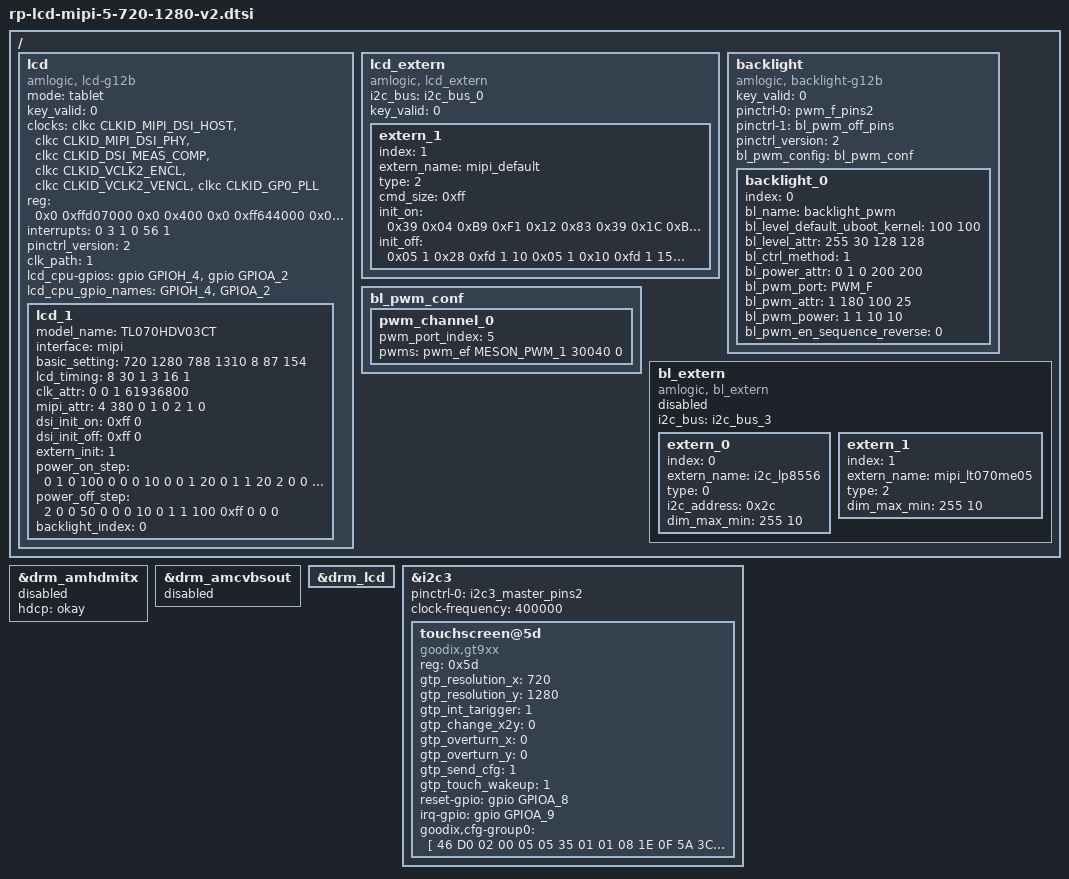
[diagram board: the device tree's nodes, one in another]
/*
 * arch/arm/boot/dts/amlogic/mesong12b_skt-panel.dtsi
 *
 * Copyright (C) 2016 Amlogic, Inc. All rights reserved.
 *
 * This program is free software; you can redistribute it and/or modify
 * it under the terms of the GNU General Public License as published by
 * the Free Software Foundation; either version 2 of the License, or
 * (at your option) any later version.
 *
 * This program is distributed in the hope that it will be useful, but WITHOUT
 * ANY WARRANTY; without even the implied warranty of MERCHANTABILITY or
 * FITNESS FOR A PARTICULAR PURPOSE.  See the GNU General Public License for
 * more details.
 *
 */

/ {
	lcd{
		compatible = "amlogic, lcd-g12b";
		mode = "tablet";
		status = "okay";
		key_valid = <0>;
		clocks = <&clkc CLKID_MIPI_DSI_HOST
			&clkc CLKID_MIPI_DSI_PHY
			&clkc CLKID_DSI_MEAS_COMP
			&clkc CLKID_VCLK2_ENCL
			&clkc CLKID_VCLK2_VENCL
			&clkc CLKID_GP0_PLL>;
		clock-names = "dsi_host_gate",
			"dsi_phy_gate",
			"dsi_meas",
			"encl_top_gate",
			"encl_int_gate",
			"gp0_pll";
		reg = <0x0 0xffd07000 0x0 0x400    /* dsi_host */
			0x0 0xff644000 0x0 0x200>; /* dsi_phy */
		interrupts = <0 3 1
			0 56 1>;
		interrupt-names = "vsync","vsync2";
		pinctrl_version = <2>; /* for uboot */
		clk_path = <1>; /* default gp0 pll */

        /* power type:
         *    (0=cpu_gpio, 1=pmu_gpio, 2=signal,3=extern, 0xff=ending)
         * power index:
         *    (point gpios_index, or extern_index,0xff=invalid)
         * power value:(0=output low, 1=output high, 2=input)
         * power delay:(unit in ms)
         */
        lcd_cpu-gpios = <
            &gpio GPIOH_4 GPIO_ACTIVE_HIGH
            &gpio GPIOA_2 GPIO_ACTIVE_HIGH>;
                         
        lcd_cpu_gpio_names = "GPIOH_4","GPIOA_2";

        lcd_1{
            model_name = "TL070HDV03CT";
            interface = "mipi";
            basic_setting = <
                720 1280  /*h_active, v_active*/
                788 1310  /*h_period, v_period*/
                8         /*lcd_bits*/
                87 154 >; /*screen_widht, screen_height*/
                             
            lcd_timing = <
                8  30 1    /*hs_width, hs_bp, hs_pol*/
                3  16 1 >; /*vs_width, vs_bp, vs_pol*/
            
            clk_attr = <
                0           /*fr_adj_type(0=clk, 1=htotal, 2=vtotal)*/
                0           /*clk_ss_level */
                1           /*clk_auto_generate*/
                61936800>;  /*pixel_clk(unit in Hz)*/
                        
            mipi_attr = <
                4   /*lane_num*/
                380 /*bit_rate_max(MHz)*/
                0   /*factor(*100, default 0 for auto)*/
                1   /*operation_mode_init(0=video, 1=command)*/
                0   /*operation_mode_display(0=video, 1=command)*/
                2   /*
                    *video_mode_type
                    *(0=sync_pulse,1=sync_event,2=burst)
                    */
                1   /*clk_always_hs(0=disable,1=enable)*/
                0 >; /*phy_switch(0=auto,1=standard,2=slow)*/

            /* dsi_init: data_type, num, data... */
            dsi_init_on = <0xff 0>; /*ending*/
            dsi_init_off = <0xff 0>; /*ending*/
            extern_init = <1>; /*0xff for invalid*/

            /* power step: type, index, value, delay(ms) */
            power_on_step = <
                0 1 0 100
                0 0 0 10
                0 0 1 20
                0 1 1 20
                2 0 0 0
                0xff 0 0 0>; /*ending*/
            power_off_step = <
                2 0 0 50
                0 0 0 10
                0 1 1 100
                0xff 0 0 0>; /*ending*/
            backlight_index = <0>;
        };
    };

    lcd_extern{
        compatible = "amlogic, lcd_extern";
        status = "okay";
        i2c_bus = "i2c_bus_0";
        key_valid = <0>;

        extern_1{
            index = <1>;
            extern_name = "mipi_default";/*P070ACB_FT*/
            status = "okay";
            type = <2>; /* 0=i2c, 1=spi, 2=mipi */
            cmd_size = <0xff>;
            init_on = <
                0x39 0x04 0xB9 0xF1 0x12 0x83
                0x39 0x1C 0xBA 0x33 0x81 0x05 0xF9 0x0E 0x0E 0x20 0x00 0x00 0x00 0x00 0x00 0x00 0x00 0x44 0x25 0x00 0x91 0x0A 0x00 0x00 0x02 0x4F 0xD1 0x00 0x00 0x37
                0x15 0x02 0xB8 0x26
                0x39 0x04 0xBF 0x02 0x10 0x00
                0x39 0x0B 0xB3 0x07 0x0B 0x1E 0x1E 0x03 0xFF 0x00 0x00 0x00 0x00
                0x39 0x0A 0xC0 0x73 0x73 0x50 0x50 0x00 0x00 0x08 0x70 0x00
                0x15 0x02 0xBC 0x46
                0x15 0x02 0xCC 0x0B
                0x15 0x02 0xB4 0x80
                0x39 0x04 0xB2 0xC8 0x12 0xA0
                0x39 0x0F 0xE3 0x07 0x07 0x0B 0x0B 0x03 0x0B 0x00 0x00 0x00 0x00 0xFF 0x80 0xC0 0x10
                0x39 0x0D 0xC1 0x53 0x00 0x32 0x32 0x77 0xF1 0xFF 0xFF 0xCC 0xCC 0x77 0x77
                0x39 0x03 0xB5 0x09 0x09
                0x39 0x03 0xB6 0xB7 0xB7
                0x39 0x40 0xE9 0xC2 0x10 0x0A 0x00 0x00 0x81 0x80 0x12 0x30 0x00 0x37 0x86 0x81 0x80 0x37 0x18 0x00 0x05 0x00 0x00 0x00 0x00 0x00 0x05 0x00 0x00 0x00 0x00 0xF8 0xBA 0x46 0x02 0x08 0x28 0x88 0x88 0x88 0x88 0x88 0xF8 0xBA 0x57 0x13 0x18 0x38 0x88 0x88 0x88 0x88 0x88 0x00 0x00 0x00 0x03 0x00 0x00 0x00 0x00 0x00 0x00 0x00 0x00 0x00
                0x39 0x3E 0xEA 0x07 0x12 0x01 0x01 0x02 0x3C 0x00 0x00 0x00 0x00 0x00 0x00 0x8F 0xBA 0x31 0x75 0x38 0x18 0x88 0x88 0x88 0x88 0x88 0x8F 0xBA 0x20 0x64 0x28 0x08 0x88 0x88 0x88 0x88 0x88 0x23 0x10 0x00 0x00 0x04 0x00 0x00 0x00 0x00 0x00 0x00 0x00 0x00 0x00 0x00 0x00 0x00 0x00 0x00 0x00 0x00 0x00 0x00 0x00 0x00 0x00 0x00
                0x39 0x23 0xE0 0x00 0x02 0x04 0x1A 0x23 0x3F 0x2C 0x28 0x05 0x09 0x0B 0x10 0x11 0x10 0x12 0x12 0x19 0x00 0x02 0x04 0x1A 0x23 0x3F 0x2C 0x28 0x05 0x09 0x0B 0x10 0x11 0x10 0x12 0x12 0x19
                0xfd 1 200   /* delay(ms) */
                0x05 1 0x11  /* sleep out */
                0x05 1 0x29 /* display on */
                0xff 0>;    /*ending*/
                
            init_off = <
                0x05 1 0x28 /* display off */
                0xfd 1 10   /* delay 10ms */
                0x05 1 0x10 /* sleep in */
                0xfd 1 150  /* delay 150ms */
                0xff 0>;    /*ending*/
        };
    };

    backlight{
        compatible = "amlogic, backlight-g12b";
        status = "okay";
        key_valid = <0>;
        pinctrl-names = "pwm_on","pwm_off";
        pinctrl-0 = <&pwm_f_pins2>;
        pinctrl-1 = <&bl_pwm_off_pins>;
        pinctrl_version = <2>; /* for uboot */
        bl_pwm_config = <&bl_pwm_conf>;
        //bl-gpios = <&gpio GPIOH_4 GPIO_ACTIVE_HIGH
        //&gpio GPIOH_5 GPIO_ACTIVE_HIGH>;
        //bl_gpio_names = "GPIOH_4","GPIOH_5";

        //bl-gpios = <&gpio GPIOH_5 GPIO_ACTIVE_HIGH>;
        //bl_gpio_names = "GPIOH_5";

        /* pwm port: PWM_A, PWM_B, PWM_C, PWM_D, PWM_E, PWM_F, PWM_VS*/
        /* power index:(point gpios_index, 0xff=invalid)
         * power value:(0=output low, 1=output high, 2=input)
         * power delay:(unit in ms)
         */

        backlight_0{
            index = <0>;
            bl_name = "backlight_pwm";
            bl_level_default_uboot_kernel = <100 100>;
            bl_level_attr = <255 30     /*max, min*/
                             128 128>;  /*mid, mid_mapping*/
                             
            bl_ctrl_method = <1>; /* 1=pwm, 2=pwm_combo, 4=extern */
            
            bl_power_attr = <0          /*en_gpio_index*/
                            1 0         /*on_value, off_value*/
                            200 200>;   /*on_delay(ms), off_delay(ms)*/
                            
            bl_pwm_port = "PWM_F";
            bl_pwm_attr = < 1        /*pwm_method*/
                            180      /*pwm_freq(pwm:Hz, pwm_vs:multiple of vs)*/
                            100 25>; /*duty_max(%), duty_min(%)*/
                            
            bl_pwm_power = <1 1     /*pwm_gpio_index, pwm_gpio_off*/
                            10 10>; /*pwm_on_delay(ms), pwm_off_delay(ms)*/
                            
            bl_pwm_en_sequence_reverse = <0>; /* 1 for reverse */
        };
    };
    
    bl_pwm_conf:bl_pwm_conf{
        pwm_channel_0 {
            pwm_port_index = <5>;
            pwms = <&pwm_ef MESON_PWM_1 30040 0>;
        };
    };

    bl_extern{
        compatible = "amlogic, bl_extern";
        status = "disabled";
        i2c_bus = "i2c_bus_3";

        extern_0{
            index = <0>;
            extern_name = "i2c_lp8556";
            type = <0>; /*0=i2c, 1=spi, 2=mipi*/
            i2c_address = <0x2c>; /*7bit i2c address*/
            dim_max_min = <255 10>;
        };

        extern_1{
            index = <1>;
            extern_name = "mipi_lt070me05";
            type = <2>; /*0=i2c, 1=spi, 2=mipi*/
            dim_max_min = <255 10>;
        };
    };
};/* end of panel */

&drm_amhdmitx {
	status = "disable";
	hdcp = "okay";
};

&drm_amcvbsout {
	status = "disable";
};

&drm_lcd {
	status = "okay";
};



&i2c3 { 
        status = "okay";
        pinctrl-names = "default";
        pinctrl-0 = <&i2c3_master_pins2>;
        clock-frequency = <400000>;
        
        touchscreen@5d {
                compatible = "goodix,gt9xx";
                status = "okay";
                reg = <0x5d>;
		gtp_resolution_x = <720>;
		gtp_resolution_y = <1280>;
		gtp_int_tarigger = <1>;
		gtp_change_x2y = <0>;
		gtp_overturn_x = <0>;
		gtp_overturn_y = <0>;
		gtp_send_cfg = <1>;
		gtp_touch_wakeup = <1>;
                reset-gpio = <&gpio GPIOA_8 GPIO_ACTIVE_HIGH>;
                irq-gpio = <&gpio GPIOA_9 GPIO_ACTIVE_HIGH>;
	        goodix,cfg-group0 = [
			46 D0 02 00 05 05 35 01 01 08 1E 0F 5A 3C
                        03 05 00 00 00 00 11 11 00 19 1B 1E 14 89
                        29 0A 41 43 D3 07 00 00 00 9A 02 11 00 01
                        05 00 00 00 00 09 11 00 00 36 4A 94 45 00
                        00 00 00 00 94 37 00 8B 3B 00 83 3F 00 7C
                        43 00 76 47 00 76 10 30 48 00 F0 4A 3A FF
                        FF 27 00 00 00 00 00 00 00 00 00 00 00 00
                        00 00 00 00 00 00 00 00 00 00 00 00 00 00
                        08 0A 0C 0E 10 12 14 16 18 1A 00 00 00 00
                        00 00 00 00 00 00 00 00 00 00 00 00 00 00
                        00 00 0E 0C 0A 08 06 05 04 02 00 1D 1E 1F
                        20 22 24 28 29 2A 00 00 00 00 00 00 00 00
                        00 00 00 00 00 00 00 00 00 00 00 00 00 00
                        00 00 84 01];                     	
        };
};
